# STM32MP153 register map
File version: 1.4
CPU: CM4 r0p1, little endian, no MPU, FPU, 4 interrupt priority bits
Registers are 32-bit, read-write, reset 0x0 unless marked. A register's access mark holds for its fields unless they carry their own. Offsets are from the block's base; [hi:lo] are bit positions; {n}, {i} and the like mark numbered series.

## EXTI
Base 0x5000D000
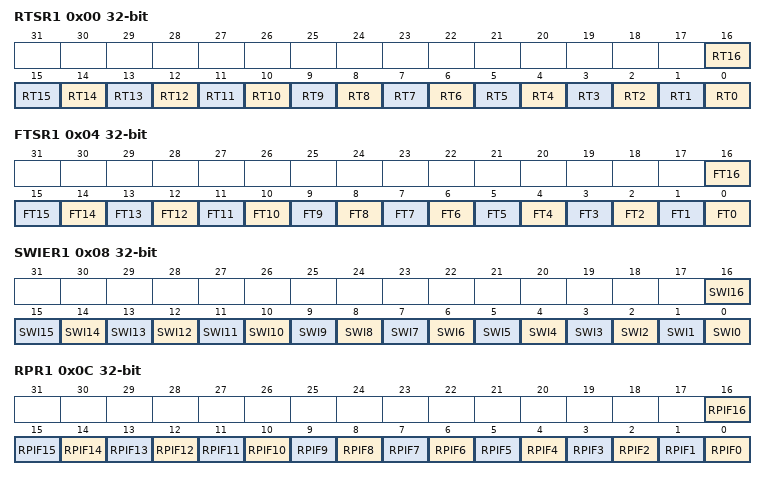
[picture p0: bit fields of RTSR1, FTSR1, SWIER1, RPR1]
0x00 RTSR1 — Contains only register bits for configurable events.
  [n] RT{n} (n=0..16)
0x04 FTSR1 — Contains only register bits for configurable events.
  [n] FT{n} (n=0..16)
0x08 SWIER1 — Contains only register bits for configurable events.
  [n] SWI{n} (n=0..16)
0x0C RPR1 — Contains only register bits for configurable events.
  [n] RPIF{n} (n=0..16)
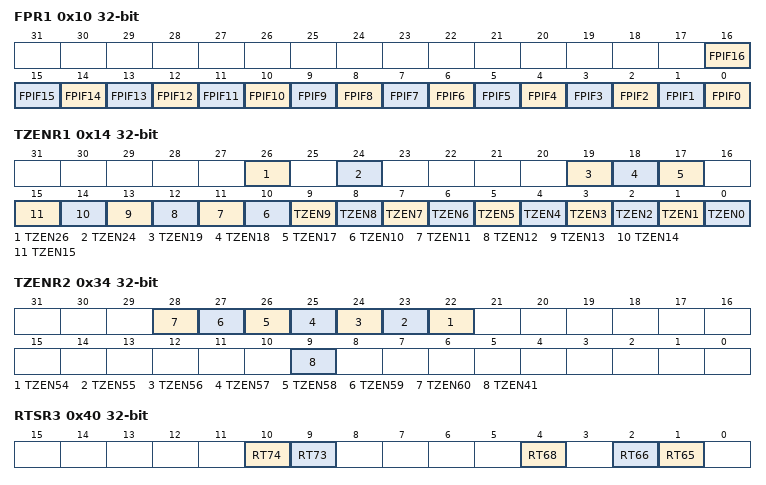
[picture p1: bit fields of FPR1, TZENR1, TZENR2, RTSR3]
0x10 FPR1 — Contains only register bits for configurable events.
  [n] FPIF{n} (n=0..16)
0x14 TZENR1 — This register provides TrustZone Write access security, a non-secure write access will generate a bus error. A non-secure read will return the register data. Contains only register bits for TrustZone capable Input events.
  [26] TZEN26, [24] TZEN24, [19] TZEN19, [18] TZEN18, [17] TZEN17, [n] TZEN{n} (n=0..15)
0x20 RTSR2 — Contains only register bits for configurable events.
0x24 FTSR2 — Contains only register bits for configurable events.
0x28 SWIER2 — Contains only register bits for configurable events.
0x2C RPR2 — Contains only register bits for configurable events.
0x30 FPR2 — Contains only register bits for configurable events.
0x34 TZENR2 — This register provides TrustZone Write access security, a non-secure write access will generate a bus error. A non-secure read will return the register data. Contains only register bits for TrustZone capable Input events.
  [n-32] TZEN{n} (n=54..60), [9] TZEN41
0x40 RTSR3 — Contains only register bits for configurable events.
  [10] RT74, [9] RT73, [4] RT68, [2] RT66, [1] RT65
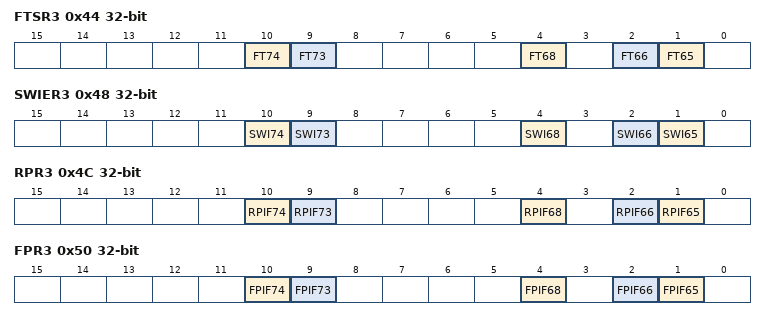
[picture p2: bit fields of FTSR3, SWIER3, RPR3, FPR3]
0x44 FTSR3 — Contains only register bits for configurable events.
  [10] FT74, [9] FT73, [4] FT68, [2] FT66, [1] FT65
0x48 SWIER3 — Contains only register bits for configurable events.
  [10] SWI74, [9] SWI73, [4] SWI68, [2] SWI66, [1] SWI65
0x4C RPR3 — Contains only register bits for configurable events.
  [10] RPIF74, [9] RPIF73, [4] RPIF68, [2] RPIF66, [1] RPIF65
0x50 FPR3 — Contains only register bits for configurable events.
  [10] FPIF74, [9] FPIF73, [4] FPIF68, [2] FPIF66, [1] FPIF65
0x54 TZENR3 — This register provides TrustZone Write access security, a non-secure write access will generate a bus error. A non-secure read will return the register data. Contains only register bits for TrustZone capable Input events.
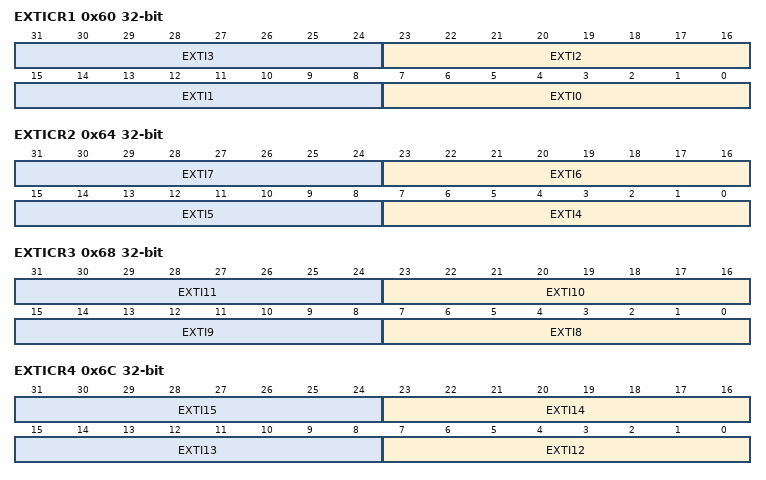
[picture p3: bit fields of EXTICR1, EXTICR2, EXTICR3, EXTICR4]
0x60 EXTICR1 — EXTIm fields contain only the number of bits in line with the nb_ioport configuration.
  [8n+7:8n] EXTI{n} (n=0..3)
0x64 EXTICR2 — EXTIm fields contain only the number of bits in line with the nb_ioport configuration.
  [8n-25:8n-32] EXTI{n} (n=4..7)
0x68 EXTICR3 — EXTIm fields contain only the number of bits in line with the nb_ioport configuration.
  [8n-57:8n-64] EXTI{n} (n=8..11)
0x6C EXTICR4 — EXTIm fields contain only the number of bits in line with the nb_ioport configuration.
  [8n-89:8n-96] EXTI{n} (n=12..15)
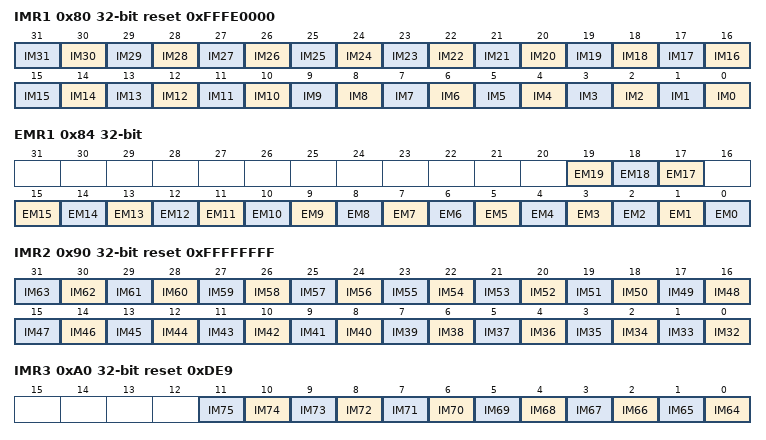
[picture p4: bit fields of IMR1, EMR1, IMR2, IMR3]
0x80 IMR1 reset 0xFFFE0000 — Contains register bits for configurable events and Direct events.
  [n] IM{n} (n=0..31)
0x84 EMR1 — EXTI CPU wakeup with event mask register
  [19] EM19, [18] EM18, [17] EM17, [n] EM{n} (n=0..15)
0x90 IMR2 reset 0xFFFFFFFF — Contains register bits for configurable events and direct events.
  [n-32] IM{n} (n=32..63)
0x94 EMR2 — EXTI CPU wakeup with event mask register
0xA0 IMR3 reset 0xDE9 — Contains register bits for configurable events and direct events.
  [n-64] IM{n} (n=64..75)
0xA4 EMR3 — EXTI CPU wakeup with event mask register
  [2] EM66
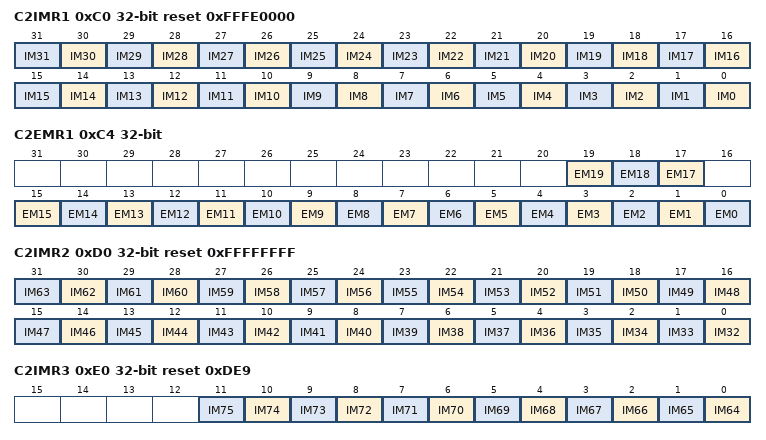
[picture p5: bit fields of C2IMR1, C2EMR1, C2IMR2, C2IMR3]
0xC0 C2IMR1 reset 0xFFFE0000 — Contains register bits for configurable events and Direct events.
  [n] IM{n} (n=0..31)
0xC4 C2EMR1 — EXTI CPU2 wakeup with event mask register
  [19] EM19, [18] EM18, [17] EM17, [n] EM{n} (n=0..15)
0xD0 C2IMR2 reset 0xFFFFFFFF — Contains register bits for configurable events and direct events.
  [n-32] IM{n} (n=32..63)
0xD4 C2EMR2 — EXTI CPU2 wakeup with event mask register
0xE0 C2IMR3 reset 0xDE9 — Contains register bits for configurable events and direct events.
  [n-64] IM{n} (n=64..75)
0xE4 C2EMR3 — EXTI CPU2 wakeup with event mask register
  [2] EM66
0x3C0 HWCFGR13 ro reset 0x50EFFFF — EXTI hardware configuration register 13
  [31:0] TZ
0x3C4 HWCFGR12 ro reset 0x50EFFFF — EXTI hardware configuration register 12
  [31:0] TZ
0x3C8 HWCFGR11 ro reset 0x50EFFFF — EXTI hardware configuration register 11
  [31:0] TZ
0x3CC HWCFGR10 ro — EXTI hardware configuration register 10
0x3D0 HWCFGR9 ro — EXTI hardware configuration register 9
0x3D4 HWCFGR8 ro — EXTI hardware configuration register 8
0x3D8 HWCFGR7 ro reset 0xEFFFF — EXTI hardware configuration register 7
  [31:0] CPUEVENT
0x3DC HWCFGR6 ro reset 0xEFFFF — EXTI hardware configuration register 6
  [31:0] CPUEVENT
0x3E0 HWCFGR5 ro reset 0xEFFFF — EXTI hardware configuration register 5
  [31:0] CPUEVENT
0x3E4 HWCFGR4 ro reset 0x1FFFF — EXTI hardware configuration register 4
  [31:0] EVENT_TRG
0x3E8 HWCFGR3 ro reset 0x1FFFF — EXTI hardware configuration register 3
  [31:0] EVENT_TRG
0x3EC HWCFGR2 ro reset 0x1FFFF — EXTI hardware configuration register 2
  [31:0] EVENT_TRG
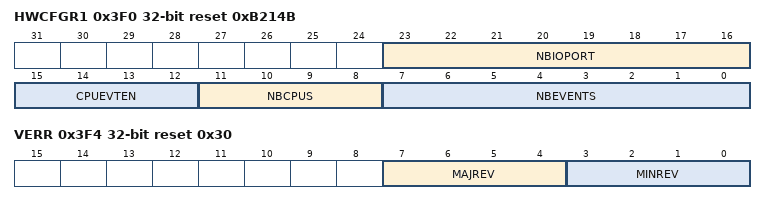
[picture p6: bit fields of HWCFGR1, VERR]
0x3F0 HWCFGR1 ro reset 0xB214B — EXTI hardware configuration register 1
  [23:16] NBIOPORT, [15:12] CPUEVTEN, [11:8] NBCPUS, [7:0] NBEVENTS
0x3F4 VERR ro reset 0x30 — EXTI IP version register
  [7:4] MAJREV, [3:0] MINREV
0x3F8 IPIDR ro reset 0xE0001 — EXTI identification register
  [31:0] IPID
0x3FC SIDR ro reset 0xA3C5DD01 — EXTI size ID register
  [31:0] SID
